# MU3E_ONEWIRE_MASTER_CONTROLLER register map
Vendor: Mu3e; Series: MU3E_FPGA_IP; File version: 24.0.918
CMSIS-SVD description of the onewire_master_controller CSR aperture. BaseAddress is 0 because this file describes the relative CSR aperture of the IP; system integration supplies the live slave base address.
Registers are 32-bit, read-only, reset 0x0 unless marked. A register's access mark holds for its fields unless they carry their own. Offsets are from the block's base; lines under a group give offsets from that group; [hi:lo] are bit positions; {n}, {i} and the like mark numbered series; 'fields as' and 'values as' point back to an identical list; <NAME> marks a mode.

## Memory map
0x00000000 ONEWIRE_MASTER_CONTROLLER_CSR size 0x20 — Relative 8-word 1-Wire controller CSR aperture.

## ONEWIRE_MASTER_CONTROLLER_CSR — Relative 8-word 1-Wire controller CSR aperture.
Base 0x00000000
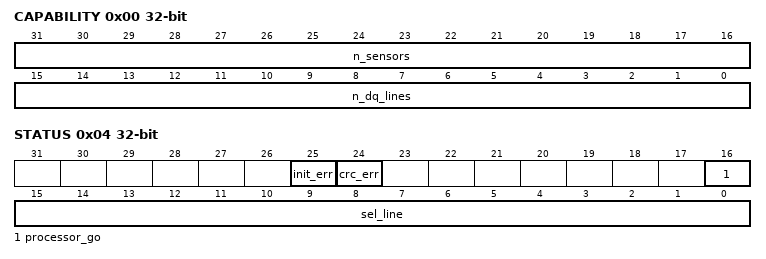
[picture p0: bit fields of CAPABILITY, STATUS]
0x00 CAPABILITY — 1-Wire controller capability register.
  [31:16] n_sensors — Reserved for future sensor-count reporting; currently reads zero.
  [15:0] n_dq_lines — Number of 1-Wire DQ lines synthesized into this instance.
0x04 STATUS rw — Line select and per-line control/status register. Reads return the selected line and its sticky error summary. Writes update sel_line and processor_go for the addressed line.
  [25] init_err ro — Initialization error sticky flag for the selected line.
  [24] crc_err ro — CRC error sticky flag for the selected line.
  [16] processor_go — Enable or disable the background measurement processor for the selected line.
  [15:0] sel_line — Selected DQ line index for readback and processor_go writes.
{0x8+4i} SENSOR{i}_TEMP_F32 (i=0..5) — IEEE-754 float32 temperature reading for sensor {i}.
  [31:0] value — Raw float32 temperature sample for sensor {i}.
